# LPC43xx register map
File version: 10
CPU: CM4 r0p0, little endian, no MPU, no FPU, 3 interrupt priority bits
Registers are 32-bit, read-write, reset 0x0 unless marked. A register's access mark holds for its fields unless they carry their own. Offsets are from the block's base; [hi:lo] are bit positions; {n}, {i} and the like mark numbered series; 'fields as' and 'values as' point back to an identical list.

## ATIMER — Alarm timer
Base 0x40040000
0x00 DOWNCOUNTER
  [15:0] CVAL — When equal to zero an interrupt is raised. When equal to zero PRESET is loaded and counting continues.
0x04 PRESET — Preset value register
  [15:0] PRESETVAL — Value loaded in DOWNCOUNTER when DOWNCOUNTER equals zero
0xFD8 CLR_EN wo — Interrupt clear enable register
  [0] CLR_EN — Writing a 1 to this bit clears the interrupt enable bit in the ENABLE register.
0xFDC SET_EN wo — Interrupt set enable register
  [0] SET_EN — Writing a 1 to this bit sets the interrupt enable bit in the ENABLE register.
0xFE0 STATUS ro
  [0] STAT — A 1 in this bit shows that the STATUS interrupt has been raised.
0xFE4 ENABLE ro
  [0] EN — A 1 in this bit shows that the STATUS interrupt has been enabled and that the STATUS interrupt request signal is asserted when STAT = 1 in the STATUS register.
0xFE8 CLR_STAT wo — Clear register
  [0] CSTAT — Writing a 1 to this bit clears the STATUS interrupt bit in the STATUS register.
0xFEC SET_STAT wo — Set register
  [0] SSTAT — Writing a 1 to this bit sets the STATUS interrupt bit in the STATUS register.

## REGFILE — RTC REGFILE
Base 0x40041000
{0x0+4i} REGFILE[{i}] (i=0..63) — General purpose storage register
  [31:0] REGVAL — General purpose storage.

## PMC — Power Management Controller (PMC)
Base 0x40042000
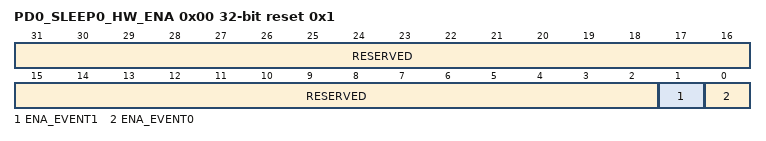
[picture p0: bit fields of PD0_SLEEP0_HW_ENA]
0x00 PD0_SLEEP0_HW_ENA reset 0x1 — Hardware sleep event enable register
  [31:2] RESERVED — Reserved, user software should not write ones to reserved bits. The value read from a reserved bit is not defined.
  [1] ENA_EVENT1 — Writing a 1 enables the Cortex-M0 core and the Cortex-M0 subsystem core to put the part into any of the Power-down modes Deep-sleep, Power-down, or Deep power-down depending on the value in the PD0_SLEEP0_MODE register.
  [0] ENA_EVENT0 — Writing a 1 enables the Cortex-M4 core to put the part into any of the Power-down modes Deep-sleep, Power-down, or Deep power-down depending on the value in the PD0_SLEEP0_MODE register.
0x1C PD0_SLEEP0_MODE reset 0x3FFF7F — Sleep power mode register
  [31:0] PWR_STATE — Selects between Deep-sleep, Power-down, and Deep power-down modes. Only one of the following three values can be programmed in this register: 0x0030 00AA = Deep-sleep mode 0x0030 FCBA = Power-down mode 0x0030 3CBA = Power-down mode with M0SUB SRAM maintained 0x0030 FF7F = Deep power-down mode

## CCU2 — Clock Control Unit (CCU2)
Base 0x40052000
0x00 PM — Power mode register
  [0] PD — Initiate power-down mode
    0=NORMAL_OPERATION_; 1=CLOCKS_WITH_WAKE_UP_ (Clocks with wake-up mode enabled (W = 1) are disabled.)
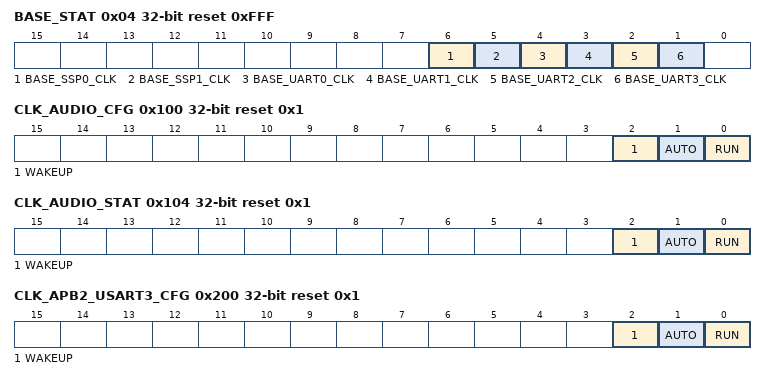
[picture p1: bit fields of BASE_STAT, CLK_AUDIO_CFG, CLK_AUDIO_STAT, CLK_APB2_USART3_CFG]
0x04 BASE_STAT ro reset 0xFFF — CCU base clocks status register
  [6] BASE_SSP0_CLK — Base clock indicator for BASE_SSP0_CLK 0 = All branch clocks switched off. 1 = At least one branch clock running.
  [5] BASE_SSP1_CLK — Base clock indicator for BASE_SSP1_CLK 0 = All branch clocks switched off. 1 = At least one branch clock running.
  [4-n] BASE_UART{n}_CLK (n=0..3) — Base clock indicator for BASE_UART{n}_CLK 0 = All branch clocks switched off. 1 = At least one branch clock running.
0x100 CLK_AUDIO_CFG reset 0x1 — CLK_AUDIO clock configuration register
  [2] WAKEUP — Wake-up mechanism enable
    0=DISABLED (Wake-up is disabled.); 1=ENABLED (Wake-up is enabled.)
  [1] AUTO — Auto (AHB disable mechanism) enable
    0=DISABLED_ (Auto is disabled.); 1=ENABLED (Auto is enabled.)
  [0] RUN — Run enable
    0=DISABLED (Clock is disabled.); 1=ENABLED (Clock is enabled.)
0x104 CLK_AUDIO_STAT ro reset 0x1 — CLK_AUDIO clock status register
  [2] WAKEUP — Wake-up mechanism enable status 0 = Wake-up is disabled. 1 = Wake-up is enabled.
  [1] AUTO — Auto (AHB disable mechanism) enable status 0 = Auto is disabled. 1 = Auto is enabled.
  [0] RUN — Run enable status 0 = clock is disabled. 1 = clock is enabled.
0x200 CLK_APB2_USART3_CFG reset 0x1 — CLK_APB2_USART3 clock configuration register
  fields as CLK_AUDIO_CFG
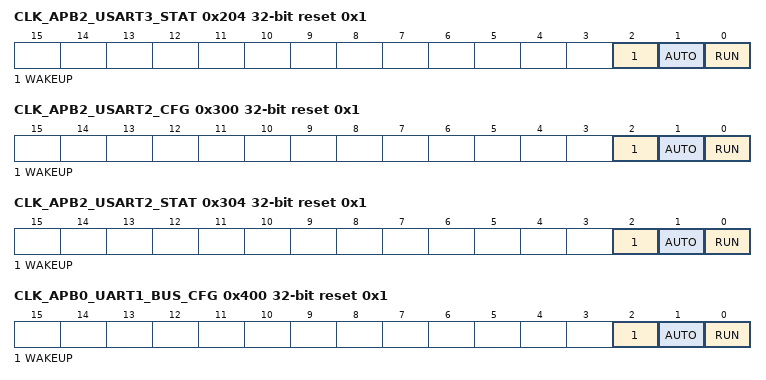
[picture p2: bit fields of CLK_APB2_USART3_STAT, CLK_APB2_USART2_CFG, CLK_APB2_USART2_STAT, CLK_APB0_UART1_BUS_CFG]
0x204 CLK_APB2_USART3_STAT ro reset 0x1 — CLK_APB2_USART3 clock status register
  fields as CLK_AUDIO_STAT
0x300 CLK_APB2_USART2_CFG reset 0x1 — CLK_APB2_USART2 clock configuration register
  fields as CLK_AUDIO_CFG
0x304 CLK_APB2_USART2_STAT ro reset 0x1 — CLK_APB2_USART clock status register
  fields as CLK_AUDIO_STAT
0x400 CLK_APB0_UART1_BUS_CFG reset 0x1 — CLK_APB2_UART1 clock configuration register
  fields as CLK_AUDIO_CFG
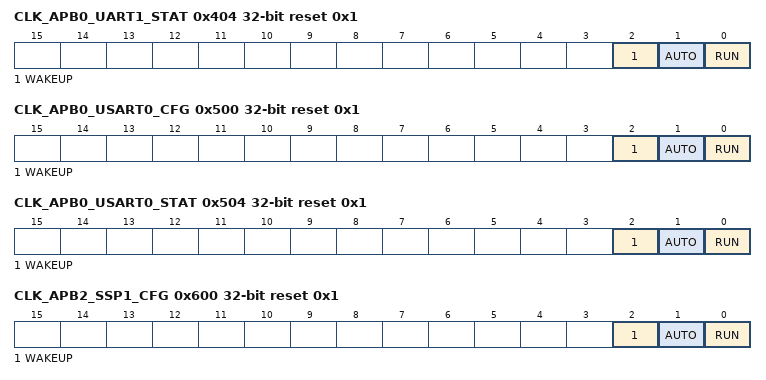
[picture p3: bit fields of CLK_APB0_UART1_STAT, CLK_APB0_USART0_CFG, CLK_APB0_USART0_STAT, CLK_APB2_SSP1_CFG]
0x404 CLK_APB0_UART1_STAT ro reset 0x1 — CLK_APB0_UART1 clock status register
  fields as CLK_AUDIO_STAT
0x500 CLK_APB0_USART0_CFG reset 0x1 — CLK_APB2_USART0 clock configuration register
  fields as CLK_AUDIO_CFG
0x504 CLK_APB0_USART0_STAT ro reset 0x1 — CLK_APB0_USART0 clock status register
  fields as CLK_AUDIO_STAT
0x600 CLK_APB2_SSP1_CFG reset 0x1 — CLK_APB2_SSP1 clock configuration register
  fields as CLK_AUDIO_CFG
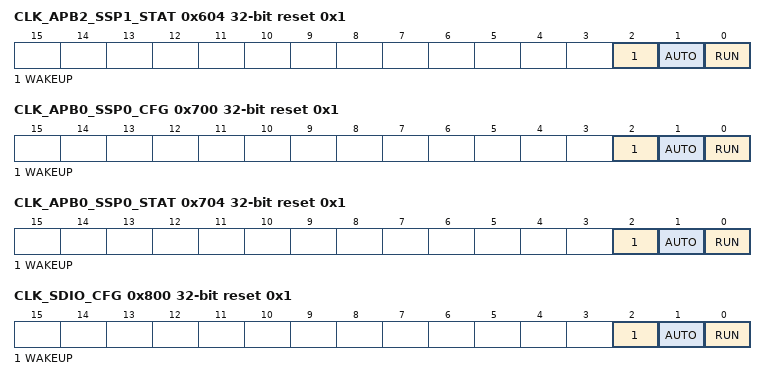
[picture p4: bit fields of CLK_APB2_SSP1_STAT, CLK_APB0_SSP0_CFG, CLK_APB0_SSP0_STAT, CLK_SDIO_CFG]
0x604 CLK_APB2_SSP1_STAT ro reset 0x1 — CLK_APB2_SSP1 clock status register
  fields as CLK_AUDIO_STAT
0x700 CLK_APB0_SSP0_CFG reset 0x1 — CLK_APB0_SSP0 clock configuration register
  fields as CLK_AUDIO_CFG
0x704 CLK_APB0_SSP0_STAT ro reset 0x1 — CLK_APB0_SSP0 clock status register
  fields as CLK_AUDIO_STAT
0x800 CLK_SDIO_CFG reset 0x1 — CLK_SDIO clock configuration register
  fields as CLK_AUDIO_CFG
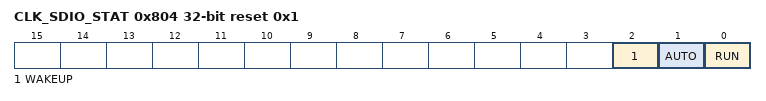
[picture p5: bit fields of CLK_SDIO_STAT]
0x804 CLK_SDIO_STAT ro reset 0x1 — CLK_SDIO clock status register
  fields as CLK_AUDIO_STAT
